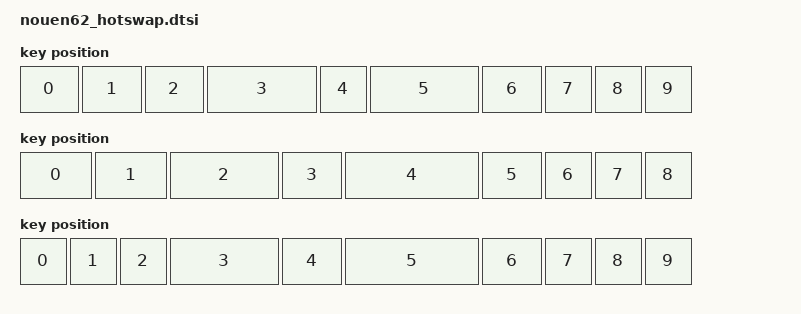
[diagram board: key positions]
#include <physical_layouts.dtsi>

/* 66 PCB switch circuits; selectable presets match the seven bottom rows. */
#define COMMON_KEYS \
<&key_physical_attrs 100 100 0 0 0 0 0>,<&key_physical_attrs 100 100 100 0 0 0 0>,<&key_physical_attrs 100 100 200 0 0 0 0>,<&key_physical_attrs 100 100 300 0 0 0 0>,<&key_physical_attrs 100 100 400 0 0 0 0>,<&key_physical_attrs 100 100 500 0 0 0 0>,<&key_physical_attrs 100 100 600 0 0 0 0>,<&key_physical_attrs 100 100 700 0 0 0 0>,<&key_physical_attrs 100 100 800 0 0 0 0>,<&key_physical_attrs 100 100 900 0 0 0 0>,<&key_physical_attrs 100 100 1000 0 0 0 0>,<&key_physical_attrs 100 100 1100 0 0 0 0>,<&key_physical_attrs 100 100 1200 0 0 0 0>,<&key_physical_attrs 100 100 1300 0 0 0 0>,<&key_physical_attrs 100 100 1400 0 0 0 0>, \
<&key_physical_attrs 150 100 0 100 0 0 0>,<&key_physical_attrs 100 100 150 100 0 0 0>,<&key_physical_attrs 100 100 250 100 0 0 0>,<&key_physical_attrs 100 100 350 100 0 0 0>,<&key_physical_attrs 100 100 450 100 0 0 0>,<&key_physical_attrs 100 100 550 100 0 0 0>,<&key_physical_attrs 100 100 650 100 0 0 0>,<&key_physical_attrs 100 100 750 100 0 0 0>,<&key_physical_attrs 100 100 850 100 0 0 0>,<&key_physical_attrs 100 100 950 100 0 0 0>,<&key_physical_attrs 100 100 1050 100 0 0 0>,<&key_physical_attrs 100 100 1150 100 0 0 0>,<&key_physical_attrs 100 100 1250 100 0 0 0>,<&key_physical_attrs 150 100 1350 100 0 0 0>, \
<&key_physical_attrs 175 100 0 200 0 0 0>,<&key_physical_attrs 100 100 175 200 0 0 0>,<&key_physical_attrs 100 100 275 200 0 0 0>,<&key_physical_attrs 100 100 375 200 0 0 0>,<&key_physical_attrs 100 100 475 200 0 0 0>,<&key_physical_attrs 100 100 575 200 0 0 0>,<&key_physical_attrs 100 100 675 200 0 0 0>,<&key_physical_attrs 100 100 775 200 0 0 0>,<&key_physical_attrs 100 100 875 200 0 0 0>,<&key_physical_attrs 100 100 975 200 0 0 0>,<&key_physical_attrs 100 100 1075 200 0 0 0>,<&key_physical_attrs 100 100 1175 200 0 0 0>,<&key_physical_attrs 225 100 1275 200 0 0 0>, \
<&key_physical_attrs 125 100 0 300 0 0 0>,<&key_physical_attrs 100 100 125 300 0 0 0>,<&key_physical_attrs 100 100 225 300 0 0 0>,<&key_physical_attrs 100 100 325 300 0 0 0>,<&key_physical_attrs 100 100 425 300 0 0 0>,<&key_physical_attrs 100 100 525 300 0 0 0>,<&key_physical_attrs 100 100 625 300 0 0 0>,<&key_physical_attrs 100 100 725 300 0 0 0>,<&key_physical_attrs 100 100 825 300 0 0 0>,<&key_physical_attrs 100 100 925 300 0 0 0>,<&key_physical_attrs 100 100 1025 300 0 0 0>,<&key_physical_attrs 100 100 1125 300 0 0 0>,<&key_physical_attrs 100 100 1225 300 0 0 0>,<&key_physical_attrs 175 100 1325 300 0 0 0>

#define COMMON_POS 0 1 2 3 4 5 6 7 8 9 10 11 12 13 14 15 16 17 18 19 20 21 22 23 24 25 26 27 28 29 30 31 32 33 34 35 36 37 38 39 40 41 42 43 44 45 46 47 48 49 50 51 52 53 54 55

/ {
 all_layout: all_layout {
  compatible = "zmk,physical-layout"; display-name = "All switch positions"; kscan = <&kscan0>; transform = <&matrix_transform_0>;
  keys = COMMON_KEYS,
   <&key_physical_attrs 125 100 75 400 0 0 0>,<&key_physical_attrs 125 100 200 400 0 0 0>,<&key_physical_attrs 125 100 325 400 0 0 0>,<&key_physical_attrs 225 100 450 400 0 0 0>,<&key_physical_attrs 100 100 675 400 0 0 0>,<&key_physical_attrs 225 100 775 400 0 0 0>,<&key_physical_attrs 125 100 1000 400 0 0 0>,<&key_physical_attrs 100 100 1125 400 0 0 0>,<&key_physical_attrs 100 100 1225 400 0 0 0>,<&key_physical_attrs 100 100 1325 400 0 0 0>;
 };
 split_225_275_15u_layout: split_225_275_15u_layout {
  compatible = "zmk,physical-layout"; display-name = "1.5u - 2.25/2.75 split"; kscan = <&kscan0>;
  keys = COMMON_KEYS,<&key_physical_attrs 150 100 75 400 0 0 0>,<&key_physical_attrs 150 100 225 400 0 0 0>,<&key_physical_attrs 225 100 375 400 0 0 0>,<&key_physical_attrs 125 100 600 400 0 0 0>,<&key_physical_attrs 275 100 725 400 0 0 0>,<&key_physical_attrs 125 100 1000 400 0 0 0>,<&key_physical_attrs 100 100 1125 400 0 0 0>,<&key_physical_attrs 100 100 1225 400 0 0 0>,<&key_physical_attrs 100 100 1325 400 0 0 0>;
 };
 split_225_275_1u_layout: split_225_275_1u_layout {
  compatible = "zmk,physical-layout"; display-name = "3x1u - 2.25/2.75 split"; kscan = <&kscan0>;
  keys = COMMON_KEYS,<&key_physical_attrs 100 100 75 400 0 0 0>,<&key_physical_attrs 100 100 175 400 0 0 0>,<&key_physical_attrs 100 100 275 400 0 0 0>,<&key_physical_attrs 225 100 375 400 0 0 0>,<&key_physical_attrs 125 100 600 400 0 0 0>,<&key_physical_attrs 275 100 725 400 0 0 0>,<&key_physical_attrs 125 100 1000 400 0 0 0>,<&key_physical_attrs 100 100 1125 400 0 0 0>,<&key_physical_attrs 100 100 1225 400 0 0 0>,<&key_physical_attrs 100 100 1325 400 0 0 0>;
 };
 split_275_225_15u_layout: split_275_225_15u_layout {
  compatible = "zmk,physical-layout"; display-name = "1.5u - 2.75/2.25 split"; kscan = <&kscan0>;
  keys = COMMON_KEYS,<&key_physical_attrs 150 100 75 400 0 0 0>,<&key_physical_attrs 150 100 225 400 0 0 0>,<&key_physical_attrs 275 100 375 400 0 0 0>,<&key_physical_attrs 125 100 650 400 0 0 0>,<&key_physical_attrs 225 100 775 400 0 0 0>,<&key_physical_attrs 125 100 1000 400 0 0 0>,<&key_physical_attrs 100 100 1125 400 0 0 0>,<&key_physical_attrs 100 100 1225 400 0 0 0>,<&key_physical_attrs 100 100 1325 400 0 0 0>;
 };
 split_275_225_1u_layout: split_275_225_1u_layout {
  compatible = "zmk,physical-layout"; display-name = "3x1u - 2.75/2.25 split"; kscan = <&kscan0>;
  keys = COMMON_KEYS,<&key_physical_attrs 100 100 75 400 0 0 0>,<&key_physical_attrs 100 100 175 400 0 0 0>,<&key_physical_attrs 100 100 275 400 0 0 0>,<&key_physical_attrs 275 100 375 400 0 0 0>,<&key_physical_attrs 125 100 650 400 0 0 0>,<&key_physical_attrs 225 100 775 400 0 0 0>,<&key_physical_attrs 125 100 1000 400 0 0 0>,<&key_physical_attrs 100 100 1125 400 0 0 0>,<&key_physical_attrs 100 100 1225 400 0 0 0>,<&key_physical_attrs 100 100 1325 400 0 0 0>;
 };
 space625_15u_layout: space625_15u_layout {
  compatible = "zmk,physical-layout"; display-name = "1.5u - 6.25u space"; kscan = <&kscan0>;
  keys = COMMON_KEYS,<&key_physical_attrs 150 100 75 400 0 0 0>,<&key_physical_attrs 150 100 225 400 0 0 0>,<&key_physical_attrs 625 100 375 400 0 0 0>,<&key_physical_attrs 125 100 1000 400 0 0 0>,<&key_physical_attrs 100 100 1125 400 0 0 0>,<&key_physical_attrs 100 100 1225 400 0 0 0>,<&key_physical_attrs 100 100 1325 400 0 0 0>;
 };
 space625_1u_layout: space625_1u_layout {
  compatible = "zmk,physical-layout"; display-name = "3x1u - 6.25u space"; kscan = <&kscan0>;
  keys = COMMON_KEYS,<&key_physical_attrs 100 100 75 400 0 0 0>,<&key_physical_attrs 100 100 175 400 0 0 0>,<&key_physical_attrs 100 100 275 400 0 0 0>,<&key_physical_attrs 625 100 375 400 0 0 0>,<&key_physical_attrs 125 100 1000 400 0 0 0>,<&key_physical_attrs 100 100 1125 400 0 0 0>,<&key_physical_attrs 100 100 1225 400 0 0 0>,<&key_physical_attrs 100 100 1325 400 0 0 0>;
 };
 space7u_layout: space7u_layout {
  compatible = "zmk,physical-layout"; display-name = "1.25u - 7u space"; kscan = <&kscan0>;
  keys = COMMON_KEYS,<&key_physical_attrs 125 100 75 400 0 0 0>,<&key_physical_attrs 125 100 200 400 0 0 0>,<&key_physical_attrs 700 100 325 400 0 0 0>,<&key_physical_attrs 100 100 1025 400 0 0 0>,<&key_physical_attrs 100 100 1125 400 0 0 0>,<&key_physical_attrs 100 100 1225 400 0 0 0>,<&key_physical_attrs 100 100 1325 400 0 0 0>;
 };

 position_map {
  compatible = "zmk,physical-layout-position-map";
  all { physical-layout = <&all_layout>; positions = <COMMON_POS>; };
  split22527515 { physical-layout = <&split_225_275_15u_layout>; positions = <COMMON_POS>; };
  split2252751 { physical-layout = <&split_225_275_1u_layout>; positions = <COMMON_POS>; };
  split27522515 { physical-layout = <&split_275_225_15u_layout>; positions = <COMMON_POS>; };
  split2752251 { physical-layout = <&split_275_225_1u_layout>; positions = <COMMON_POS>; };
  space62515 { physical-layout = <&space625_15u_layout>; positions = <COMMON_POS>; };
  space6251 { physical-layout = <&space625_1u_layout>; positions = <COMMON_POS>; };
  space7 { physical-layout = <&space7u_layout>; positions = <COMMON_POS>; };
 };
};

#undef COMMON_POS
#undef COMMON_KEYS
